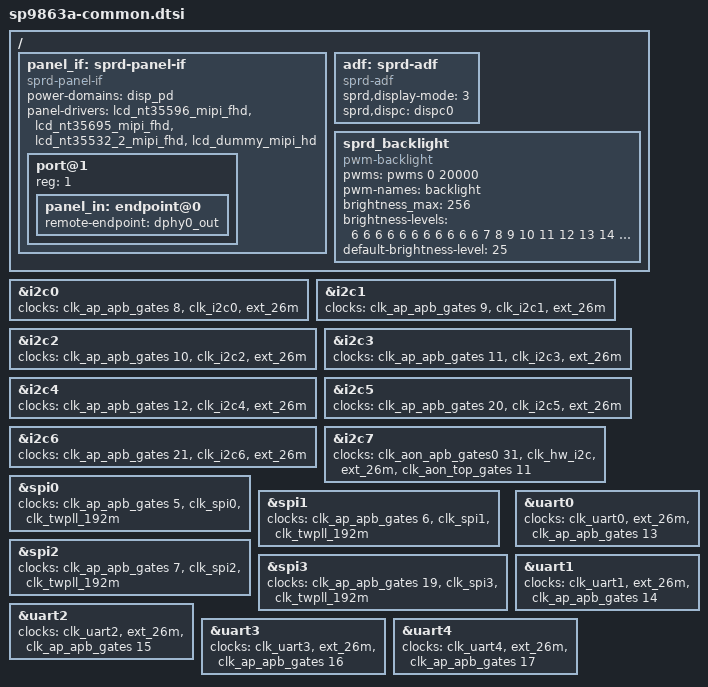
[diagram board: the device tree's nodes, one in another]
/*
 * Spreadtrum SP9863A board common DTS file
 *
 * Copyright (C) 2017, Spreadtrum Communications Inc.
 *
 * This file is licensed under a dual GPLv2 or X11 license.
 */
#include "lcd/lcd_nt35596_mipi_fhd.dtsi"
#include "lcd/lcd_nt35695_mipi_fhd.dtsi"
#include "lcd/lcd_nt35532_2_mipi_fhd.dtsi"
#include "lcd/lcd_dummy_mipi.dtsi"
#include "sc9863a-modem.dtsi"

/ {
	panel_if: sprd-panel-if {
		compatible = "sprd-panel-if";
		#address-cells = <1>;
		#size-cells = <0>;
		power-domains = <&disp_pd>;
		panel-drivers = <
			&lcd_nt35596_mipi_fhd
			&lcd_nt35695_mipi_fhd
			&lcd_nt35532_2_mipi_fhd
			&lcd_dummy_mipi_hd
		>;

		/* input port */
		port@1 {
		/* WARNING: the reg property must be 1 ! */
			reg = <1>;
			panel_in: endpoint@0 {
				remote-endpoint = <&dphy0_out>;
			};
		};
	};

	adf: sprd-adf {
		compatible = "sprd-adf";
		status = "okay";
		sprd,display-mode = <3>;
		sprd,dispc = <&dispc0>;
	};

	sprd_backlight {
		compatible = "pwm-backlight";
		pwms = <&pwms 0 20000>;
		pwm-names = "backlight";
		brightness_max = <256>;
		brightness-levels=<
						  6   6   6   6
			  6   6   6   6   6   6   6   7   8   9
			 10  11  12  13  14  15  16  17  18  19
			 20  21  22  23  24  25  26  27  28  29
			 30  31  32  33  34  35  36  37  38  39
			 40  41  42  43  44  45  46  47  48  49
			 50  51  52  53  54  55  56  57  58  59
			 60  61  62  63  64  65  66  67  68  69
			 70  71  72  73  74  75  76  77  78  79
			 80  81  82  83  84  85  86  87  88  89
			 90  91  92  93  94  95  96  97  98  99
			100 101 102 103 104 105 106 107 108 109
			110 111 112 113 114 115 116 117 118 119
			120 121 122 123 124 125 126 127 128 129
			130 131 132 133 134 135 136 137 138 139
			140 141 142 143 144 145 146 147 148 149
			150 151 152 153 154 155 156 157 158 159
			160 161 162 163 164 165 166 167 168 169
			170 171 172 173 174 175 176 177 178 179
			180 181 182 183 184 185 186 187 188 189
			190 191 192 193 194 195 196 197 198 199
			200 201 202 203 204 205 206 207 208 209
			210 211 212 213 214 215 216 217 218 219
			220 221 222 223 224 225 226 227 228 229
			230 231 232 233 234 235 236 237 238 239
			240 241 242 243 244 245 246 247 248 249
			250 251
			>;
		default-brightness-level = <25>;
	};
};

&i2c0 {
	clocks = <&clk_ap_apb_gates 8>, <&clk_i2c0>, <&ext_26m>;
};

&i2c1 {
	clocks = <&clk_ap_apb_gates 9>, <&clk_i2c1>, <&ext_26m>;
};

&i2c2 {
	clocks = <&clk_ap_apb_gates 10>, <&clk_i2c2>, <&ext_26m>;
};

&i2c3 {
	clocks = <&clk_ap_apb_gates 11>, <&clk_i2c3>, <&ext_26m>;
};

&i2c4 {
	clocks = <&clk_ap_apb_gates 12>, <&clk_i2c4>, <&ext_26m>;
};

&i2c5 {
	clocks = <&clk_ap_apb_gates 20>, <&clk_i2c5>, <&ext_26m>;
};

&i2c6 {
	clocks = <&clk_ap_apb_gates 21>, <&clk_i2c6>, <&ext_26m>;
};

&i2c7 {
	clocks = <&clk_aon_apb_gates0 31>, <&clk_hw_i2c>,
	<&ext_26m>, <&clk_aon_top_gates 11>;
};

&spi0 {
	clocks = <&clk_ap_apb_gates 5>, <&clk_spi0>, <&clk_twpll_192m>;
};

&spi1 {
	clocks = <&clk_ap_apb_gates 6>, <&clk_spi1>, <&clk_twpll_192m>;
};

&spi2 {
	clocks = <&clk_ap_apb_gates 7>, <&clk_spi2>, <&clk_twpll_192m>;
};

&spi3 {
	clocks = <&clk_ap_apb_gates 19>, <&clk_spi3>, <&clk_twpll_192m>;
};

&uart0 {
	clocks = <&clk_uart0>, <&ext_26m>, <&clk_ap_apb_gates 13>;
	status = "okay";
};

&uart1 {
	clocks = <&clk_uart1>, <&ext_26m>, <&clk_ap_apb_gates 14>;
	status = "okay";
};

&uart2 {
	clocks = <&clk_uart2>, <&ext_26m>, <&clk_ap_apb_gates 15>;
};

&uart3 {
	clocks = <&clk_uart3>, <&ext_26m>, <&clk_ap_apb_gates 16>;
};

&uart4 {
	clocks = <&clk_uart4>, <&ext_26m>, <&clk_ap_apb_gates 17>;
};
